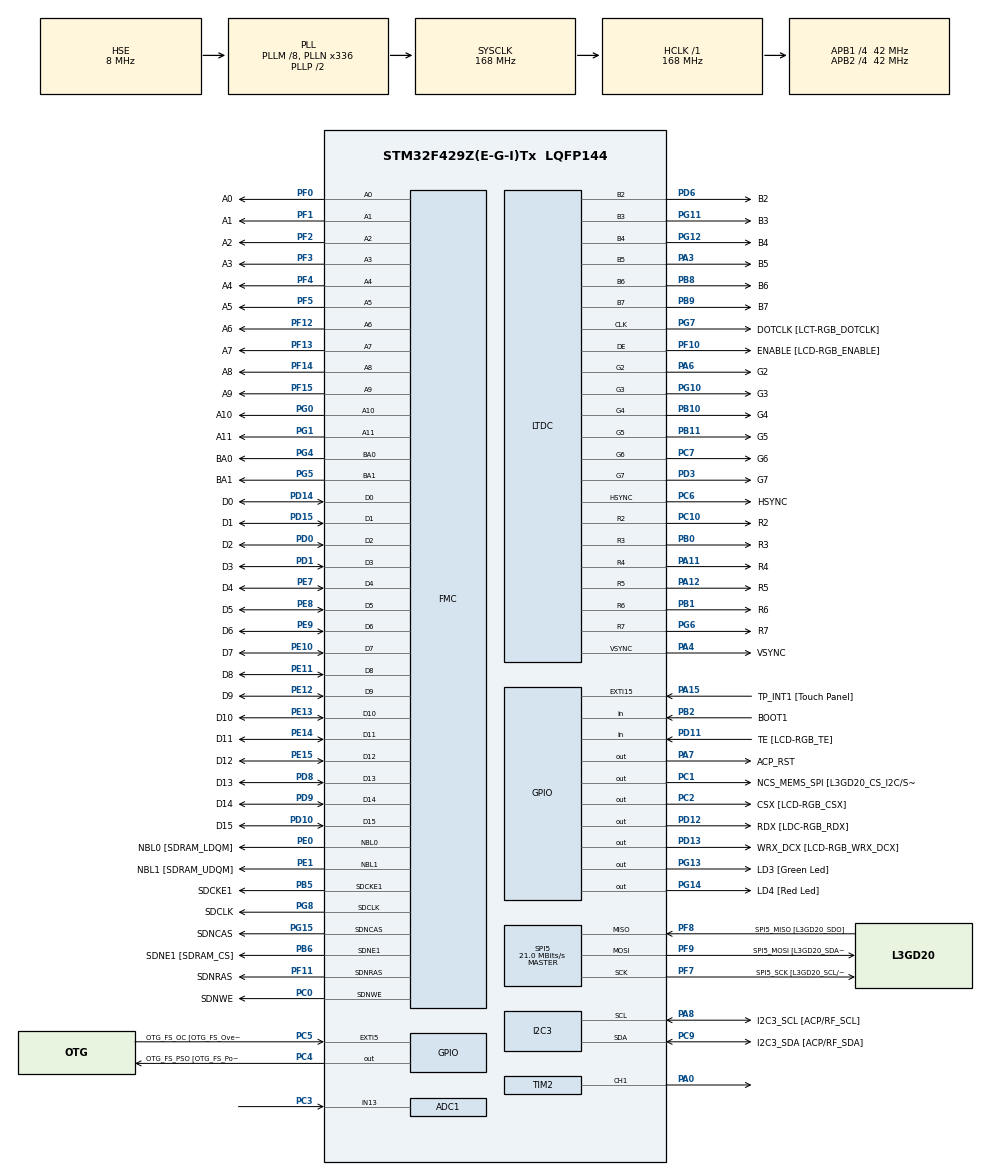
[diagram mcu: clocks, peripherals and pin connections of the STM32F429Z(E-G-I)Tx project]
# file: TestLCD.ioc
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ADC1.Channel-4\#ChannelRegularConversion=ADC_CHANNEL_13
ADC1.ClockPrescaler=ADC_CLOCK_SYNC_PCLK_DIV8
ADC1.NbrOfConversionFlag=1
ADC1.Rank-4\#ChannelRegularConversion=1
ADC1.SamplingTime-4\#ChannelRegularConversion=ADC_SAMPLETIME_15CYCLES
ADC1.ScanConvMode=ENABLE
ADC1.master=1
DMA2D.ColorMode=DMA2D_OUTPUT_RGB565
LTDC.ActiveH=240
LTDC.ActiveW=320
Mcu.Family=STM32F4
Mcu.Name=STM32F429Z(E-G-I)Tx
Mcu.Package=LQFP144
NVIC.PriorityGroup=NVIC_PRIORITYGROUP_0
NVIC.TIM1_UP_TIM10_IRQn=true\:0\:0\:false\:false\:true\:true
PA0/WKUP.Signal=S_TIM2_CH1_ETR
PA11.GPIO_Label=R4
PA11.GPIO_Mode=GPIO_MODE_AF_PP
PA11.GPIO_PuPd=GPIO_NOPULL
PA11.GPIO_Speed=GPIO_SPEED_FREQ_LOW
PA11.Mode=RGB666
PA11.Signal=LTDC_R4
PA12.GPIO_Label=R5
PA12.GPIO_Mode=GPIO_MODE_AF_PP
PA12.GPIO_PuPd=GPIO_NOPULL
PA12.GPIO_Speed=GPIO_SPEED_FREQ_LOW
PA12.Mode=RGB666
PA12.Signal=LTDC_R5
PA13.GPIO_Label=SWDIO
PA13.Mode=Serial_Wire
PA13.Signal=SYS_JTMS-SWDIO
PA14.GPIO_Label=SWCLK
PA14.Mode=Serial_Wire
PA14.Signal=SYS_JTCK-SWCLK
PA15.GPIO_Label=TP_INT1 [Touch Panel]
PA15.GPIO_ModeDefaultEXTI=GPIO_MODE_EVT_RISING
PA15.GPIO_PuPd=GPIO_NOPULL
PA15.Signal=GPXTI15
PA3.GPIO_Label=B5
PA3.GPIO_Mode=GPIO_MODE_AF_PP
PA3.GPIO_PuPd=GPIO_NOPULL
PA3.GPIO_Speed=GPIO_SPEED_FREQ_LOW
PA3.Mode=RGB666
PA3.Signal=LTDC_B5
PA4.GPIO_Label=VSYNC
PA4.GPIO_Mode=GPIO_MODE_AF_PP
PA4.GPIO_PuPd=GPIO_NOPULL
PA4.GPIO_Speed=GPIO_SPEED_FREQ_LOW
PA4.Mode=RGB666
PA4.Signal=LTDC_VSYNC
PA6.GPIO_Label=G2
PA6.GPIO_Mode=GPIO_MODE_AF_PP
PA6.GPIO_PuPd=GPIO_NOPULL
PA6.GPIO_Speed=GPIO_SPEED_FREQ_LOW
PA6.Mode=RGB666
PA6.Signal=LTDC_G2
PA7.GPIO_Label=ACP_RST
PA7.GPIO_Mode=GPIO_MODE_OUTPUT_PP
PA7.GPIO_PuPd=GPIO_NOPULL
PA7.GPIO_Speed=GPIO_SPEED_FREQ_LOW
PA7.Signal=GPIO_Output
PA8.GPIO_Label=I2C3_SCL [ACP/RF_SCL]
PA8.GPIO_Mode=GPIO_MODE_AF_OD
PA8.GPIO_PuPd=GPIO_NOPULL
PA8.GPIO_Speed=GPIO_SPEED_FREQ_LOW
PA8.Mode=I2C
PA8.Signal=I2C3_SCL
PB0.GPIO_Label=R3
PB0.GPIO_Mode=GPIO_MODE_AF_PP
PB0.GPIO_PuPd=GPIO_NOPULL
PB0.GPIO_Speed=GPIO_SPEED_FREQ_LOW
PB0.Mode=RGB666
PB0.Signal=LTDC_R3
PB1.GPIO_Label=R6
PB1.GPIO_Mode=GPIO_MODE_AF_PP
PB1.GPIO_PuPd=GPIO_NOPULL
PB1.GPIO_Speed=GPIO_SPEED_FREQ_LOW
PB1.Mode=RGB666
PB1.Signal=LTDC_R6
PB10.GPIO_Label=G4
PB10.GPIO_Mode=GPIO_MODE_AF_PP
PB10.GPIO_PuPd=GPIO_NOPULL
PB10.GPIO_Speed=GPIO_SPEED_FREQ_LOW
PB10.Mode=RGB666
PB10.Signal=LTDC_G4
PB11.GPIO_Label=G5
PB11.GPIO_Mode=GPIO_MODE_AF_PP
PB11.GPIO_PuPd=GPIO_NOPULL
PB11.GPIO_Speed=GPIO_SPEED_FREQ_LOW
PB11.Mode=RGB666
PB11.Signal=LTDC_G5
PB12.GPIO_Label=OTG_FS_ID
PB12.GPIO_Mode=GPIO_MODE_AF_PP
PB12.GPIO_PuPd=GPIO_NOPULL
PB12.GPIO_Speed=GPIO_SPEED_FREQ_LOW
PB12.Signal=USB_OTG_HS_ID
PB13.GPIO_Label=VBUS_FS
PB13.GPIO_Mode=GPIO_MODE_INPUT
PB13.GPIO_PuPd=GPIO_NOPULL
PB13.Signal=USB_OTG_HS_VBUS
PB14.GPIO_Label=OTG_FS_DM
PB14.GPIO_Mode=GPIO_MODE_AF_PP
PB14.GPIO_PuPd=GPIO_NOPULL
PB14.GPIO_Speed=GPIO_SPEED_FREQ_LOW
PB14.Signal=USB_OTG_HS_DM
PB15.GPIO_Label=OTG_FS_DP
PB15.GPIO_Mode=GPIO_MODE_AF_PP
PB15.GPIO_PuPd=GPIO_NOPULL
PB15.GPIO_Speed=GPIO_SPEED_FREQ_LOW
PB15.Signal=USB_OTG_HS_DP
PB2/BOOT1.GPIO_Label=BOOT1
PB2/BOOT1.GPIO_Mode=GPIO_MODE_INPUT
PB2/BOOT1.GPIO_PuPd=GPIO_NOPULL
PB2/BOOT1.Signal=GPIO_Input
PB5.GPIO_Label=SDCKE1
PB5.GPIO_Mode=GPIO_MODE_AF_PP
PB5.GPIO_PuPd=GPIO_NOPULL
PB5.GPIO_Speed=GPIO_SPEED_FREQ_VERY_HIGH
PB5.Mode=SdramChipSelect2_1
PB5.Signal=FMC_SDCKE1
PB6.GPIO_Label=SDNE1 [SDRAM_CS]
PB6.GPIO_Mode=GPIO_MODE_AF_PP
PB6.GPIO_PuPd=GPIO_NOPULL
PB6.GPIO_Speed=GPIO_SPEED_FREQ_VERY_HIGH
PB6.Mode=SdramChipSelect2_1
PB6.Signal=FMC_SDNE1
PB8.GPIO_Label=B6
PB8.GPIO_Mode=GPIO_MODE_AF_PP
PB8.GPIO_PuPd=GPIO_NOPULL
PB8.GPIO_Speed=GPIO_SPEED_FREQ_LOW
PB8.Mode=RGB666
PB8.Signal=LTDC_B6
PB9.GPIO_Label=B7
PB9.GPIO_Mode=GPIO_MODE_AF_PP
PB9.GPIO_PuPd=GPIO_NOPULL
PB9.GPIO_Speed=GPIO_SPEED_FREQ_LOW
PB9.Mode=RGB666
PB9.Signal=LTDC_B7
PC0.GPIO_Label=SDNWE
PC0.GPIO_Mode=GPIO_MODE_AF_PP
PC0.GPIO_PuPd=GPIO_NOPULL
PC0.GPIO_Speed=GPIO_SPEED_FREQ_VERY_HIGH
PC0.Signal=FMC_SDNWE
PC1.GPIO_Label=NCS_MEMS_SPI [L3GD20_CS_I2C/SPI]
PC1.GPIO_Mode=GPIO_MODE_OUTPUT_PP
PC1.GPIO_PuPd=GPIO_NOPULL
PC1.GPIO_Speed=GPIO_SPEED_FREQ_LOW
PC1.Signal=GPIO_Output
PC10.GPIO_Label=R2
PC10.GPIO_Mode=GPIO_MODE_AF_PP
PC10.GPIO_PuPd=GPIO_NOPULL
PC10.GPIO_Speed=GPIO_SPEED_FREQ_LOW
PC10.Mode=RGB666
PC10.Signal=LTDC_R2
PC14/OSC32_IN.GPIO_Label=PC14-OSC32_IN
PC14/OSC32_IN.Signal=RCC_OSC32_IN
PC15/OSC32_OUT.GPIO_Label=PC15-OSC32_OUT
PC15/OSC32_OUT.Signal=RCC_OSC32_OUT
PC2.GPIO_Label=CSX [LCD-RGB_CSX]
PC2.GPIO_Mode=GPIO_MODE_OUTPUT_PP
PC2.GPIO_PuPd=GPIO_NOPULL
PC2.GPIO_Speed=GPIO_SPEED_FREQ_LOW
PC2.Signal=GPIO_Output
PC3.Signal=ADCx_IN13
PC4.GPIO_Label=OTG_FS_PSO [OTG_FS_PowerSwitchOn]
PC4.GPIO_Mode=GPIO_MODE_OUTPUT_PP
PC4.GPIO_PuPd=GPIO_NOPULL
PC4.GPIO_Speed=GPIO_SPEED_FREQ_LOW
PC4.Signal=GPIO_Output
PC5.GPIO_Label=OTG_FS_OC [OTG_FS_OverCurrent]
PC5.GPIO_ModeDefaultEXTI=GPIO_MODE_EVT_RISING
PC5.Signal=GPXTI5
PC6.GPIO_Label=HSYNC
PC6.GPIO_Mode=GPIO_MODE_AF_PP
PC6.GPIO_PuPd=GPIO_NOPULL
PC6.GPIO_Speed=GPIO_SPEED_FREQ_LOW
PC6.Mode=RGB666
PC6.Signal=LTDC_HSYNC
PC7.GPIO_Label=G6
PC7.GPIO_Mode=GPIO_MODE_AF_PP
PC7.GPIO_PuPd=GPIO_NOPULL
PC7.GPIO_Speed=GPIO_SPEED_FREQ_LOW
PC7.Mode=RGB666
PC7.Signal=LTDC_G6
PC9.GPIO_Label=I2C3_SDA [ACP/RF_SDA]
PC9.GPIO_Mode=GPIO_MODE_AF_OD
PC9.GPIO_PuPd=GPIO_NOPULL
PC9.GPIO_Speed=GPIO_SPEED_FREQ_LOW
PC9.Mode=I2C
PC9.Signal=I2C3_SDA
PD0.GPIO_Label=D2
PD0.GPIO_Mode=GPIO_MODE_AF_PP
PD0.GPIO_PuPd=GPIO_NOPULL
PD0.GPIO_Speed=GPIO_SPEED_FREQ_VERY_HIGH
PD0.Signal=FMC_D2_DA2
PD1.GPIO_Label=D3
PD1.GPIO_Mode=GPIO_MODE_AF_PP
PD1.GPIO_PuPd=GPIO_NOPULL
PD1.GPIO_Speed=GPIO_SPEED_FREQ_VERY_HIGH
PD1.Signal=FMC_D3_DA3
PD10.GPIO_Label=D15
PD10.GPIO_Mode=GPIO_MODE_AF_PP
PD10.GPIO_PuPd=GPIO_NOPULL
PD10.GPIO_Speed=GPIO_SPEED_FREQ_VERY_HIGH
PD10.Signal=FMC_D15_DA15
PD11.GPIO_Label=TE [LCD-RGB_TE]
PD11.GPIO_Mode=GPIO_MODE_INPUT
PD11.GPIO_PuPd=GPIO_NOPULL
PD11.Signal=GPIO_Input
PD12.GPIO_Label=RDX [LDC-RGB_RDX]
PD12.GPIO_Mode=GPIO_MODE_OUTPUT_PP
PD12.GPIO_PuPd=GPIO_NOPULL
PD12.GPIO_Speed=GPIO_SPEED_FREQ_LOW
PD12.Signal=GPIO_Output
PD13.GPIO_Label=WRX_DCX [LCD-RGB_WRX_DCX]
PD13.GPIO_Mode=GPIO_MODE_OUTPUT_PP
PD13.GPIO_PuPd=GPIO_NOPULL
PD13.GPIO_Speed=GPIO_SPEED_FREQ_LOW
PD13.Signal=GPIO_Output
PD14.GPIO_Label=D0
PD14.GPIO_Mode=GPIO_MODE_AF_PP
PD14.GPIO_PuPd=GPIO_NOPULL
PD14.GPIO_Speed=GPIO_SPEED_FREQ_VERY_HIGH
PD14.Signal=FMC_D0_DA0
PD15.GPIO_Label=D1
PD15.GPIO_Mode=GPIO_MODE_AF_PP
PD15.GPIO_PuPd=GPIO_NOPULL
PD15.GPIO_Speed=GPIO_SPEED_FREQ_VERY_HIGH
PD15.Signal=FMC_D1_DA1
PD3.GPIO_Label=G7
PD3.GPIO_Mode=GPIO_MODE_AF_PP
PD3.GPIO_PuPd=GPIO_NOPULL
PD3.GPIO_Speed=GPIO_SPEED_FREQ_LOW
PD3.Mode=RGB666
PD3.Signal=LTDC_G7
PD6.GPIO_Label=B2
PD6.GPIO_Mode=GPIO_MODE_AF_PP
PD6.GPIO_PuPd=GPIO_NOPULL
PD6.GPIO_Speed=GPIO_SPEED_FREQ_LOW
PD6.Mode=RGB666
PD6.Signal=LTDC_B2
PD8.GPIO_Label=D13
PD8.GPIO_Mode=GPIO_MODE_AF_PP
PD8.GPIO_PuPd=GPIO_NOPULL
PD8.GPIO_Speed=GPIO_SPEED_FREQ_VERY_HIGH
PD8.Signal=FMC_D13_DA13
PD9.GPIO_Label=D14
PD9.GPIO_Mode=GPIO_MODE_AF_PP
PD9.GPIO_PuPd=GPIO_NOPULL
PD9.GPIO_Speed=GPIO_SPEED_FREQ_VERY_HIGH
PD9.Signal=FMC_D14_DA14
PE0.GPIO_Label=NBL0 [SDRAM_LDQM]
PE0.GPIO_Mode=GPIO_MODE_AF_PP
PE0.GPIO_PuPd=GPIO_NOPULL
PE0.GPIO_Speed=GPIO_SPEED_FREQ_VERY_HIGH
PE0.Signal=FMC_NBL0
PE1.GPIO_Label=NBL1 [SDRAM_UDQM]
PE1.GPIO_Mode=GPIO_MODE_AF_PP
PE1.GPIO_PuPd=GPIO_NOPULL
PE1.GPIO_Speed=GPIO_SPEED_FREQ_VERY_HIGH
PE1.Signal=FMC_NBL1
PE10.GPIO_Label=D7
PE10.GPIO_Mode=GPIO_MODE_AF_PP
PE10.GPIO_PuPd=GPIO_NOPULL
PE10.GPIO_Speed=GPIO_SPEED_FREQ_VERY_HIGH
PE10.Signal=FMC_D7_DA7
PE11.GPIO_Label=D8
PE11.GPIO_Mode=GPIO_MODE_AF_PP
PE11.GPIO_PuPd=GPIO_NOPULL
PE11.GPIO_Speed=GPIO_SPEED_FREQ_VERY_HIGH
PE11.Signal=FMC_D8_DA8
PE12.GPIO_Label=D9
PE12.GPIO_Mode=GPIO_MODE_AF_PP
PE12.GPIO_PuPd=GPIO_NOPULL
PE12.GPIO_Speed=GPIO_SPEED_FREQ_VERY_HIGH
PE12.Signal=FMC_D9_DA9
PE13.GPIO_Label=D10
PE13.GPIO_Mode=GPIO_MODE_AF_PP
PE13.GPIO_PuPd=GPIO_NOPULL
PE13.GPIO_Speed=GPIO_SPEED_FREQ_VERY_HIGH
PE13.Signal=FMC_D10_DA10
PE14.GPIO_Label=D11
PE14.GPIO_Mode=GPIO_MODE_AF_PP
PE14.GPIO_PuPd=GPIO_NOPULL
PE14.GPIO_Speed=GPIO_SPEED_FREQ_VERY_HIGH
PE14.Signal=FMC_D11_DA11
PE15.GPIO_Label=D12
PE15.GPIO_Mode=GPIO_MODE_AF_PP
PE15.GPIO_PuPd=GPIO_NOPULL
PE15.GPIO_Speed=GPIO_SPEED_FREQ_VERY_HIGH
PE15.Signal=FMC_D12_DA12
PE7.GPIO_Label=D4
PE7.GPIO_Mode=GPIO_MODE_AF_PP
PE7.GPIO_PuPd=GPIO_NOPULL
PE7.GPIO_Speed=GPIO_SPEED_FREQ_VERY_HIGH
PE7.Signal=FMC_D4_DA4
PE8.GPIO_Label=D5
PE8.GPIO_Mode=GPIO_MODE_AF_PP
PE8.GPIO_PuPd=GPIO_NOPULL
PE8.GPIO_Speed=GPIO_SPEED_FREQ_VERY_HIGH
PE8.Signal=FMC_D5_DA5
PE9.GPIO_Label=D6
PE9.GPIO_Mode=GPIO_MODE_AF_PP
PE9.GPIO_PuPd=GPIO_NOPULL
PE9.GPIO_Speed=GPIO_SPEED_FREQ_VERY_HIGH
PE9.Signal=FMC_D6_DA6
PF0.GPIO_Label=A0
PF0.GPIO_Mode=GPIO_MODE_AF_PP
PF0.GPIO_PuPd=GPIO_NOPULL
PF0.GPIO_Speed=GPIO_SPEED_FREQ_VERY_HIGH
PF0.Signal=FMC_A0
PF1.GPIO_Label=A1
PF1.GPIO_Mode=GPIO_MODE_AF_PP
PF1.GPIO_PuPd=GPIO_NOPULL
PF1.GPIO_Speed=GPIO_SPEED_FREQ_VERY_HIGH
PF1.Signal=FMC_A1
PF10.GPIO_Label=ENABLE [LCD-RGB_ENABLE]
PF10.GPIO_Mode=GPIO_MODE_AF_PP
PF10.GPIO_PuPd=GPIO_NOPULL
PF10.GPIO_Speed=GPIO_SPEED_FREQ_LOW
PF10.Mode=RGB666
PF10.Signal=LTDC_DE
PF11.GPIO_Label=SDNRAS
PF11.GPIO_Mode=GPIO_MODE_AF_PP
PF11.GPIO_PuPd=GPIO_NOPULL
PF11.GPIO_Speed=GPIO_SPEED_FREQ_VERY_HIGH
PF11.Signal=FMC_SDNRAS
PF12.GPIO_Label=A6
PF12.GPIO_Mode=GPIO_MODE_AF_PP
PF12.GPIO_PuPd=GPIO_NOPULL
PF12.GPIO_Speed=GPIO_SPEED_FREQ_VERY_HIGH
PF12.Signal=FMC_A6
PF13.GPIO_Label=A7
PF13.GPIO_Mode=GPIO_MODE_AF_PP
PF13.GPIO_PuPd=GPIO_NOPULL
PF13.GPIO_Speed=GPIO_SPEED_FREQ_VERY_HIGH
PF13.Signal=FMC_A7
PF14.GPIO_Label=A8
PF14.GPIO_Mode=GPIO_MODE_AF_PP
PF14.GPIO_PuPd=GPIO_NOPULL
PF14.GPIO_Speed=GPIO_SPEED_FREQ_VERY_HIGH
PF14.Signal=FMC_A8
PF15.GPIO_Label=A9
PF15.GPIO_Mode=GPIO_MODE_AF_PP
PF15.GPIO_PuPd=GPIO_NOPULL
PF15.GPIO_Speed=GPIO_SPEED_FREQ_VERY_HIGH
PF15.Signal=FMC_A9
PF2.GPIO_Label=A2
PF2.GPIO_Mode=GPIO_MODE_AF_PP
PF2.GPIO_PuPd=GPIO_NOPULL
PF2.GPIO_Speed=GPIO_SPEED_FREQ_VERY_HIGH
PF2.Signal=FMC_A2
PF3.GPIO_Label=A3
PF3.GPIO_Mode=GPIO_MODE_AF_PP
PF3.GPIO_PuPd=GPIO_NOPULL
PF3.GPIO_Speed=GPIO_SPEED_FREQ_VERY_HIGH
PF3.Signal=FMC_A3
PF4.GPIO_Label=A4
PF4.GPIO_Mode=GPIO_MODE_AF_PP
PF4.GPIO_PuPd=GPIO_NOPULL
PF4.GPIO_Speed=GPIO_SPEED_FREQ_VERY_HIGH
PF4.Signal=FMC_A4
PF5.GPIO_Label=A5
PF5.GPIO_Mode=GPIO_MODE_AF_PP
PF5.GPIO_PuPd=GPIO_NOPULL
PF5.GPIO_Speed=GPIO_SPEED_FREQ_VERY_HIGH
PF5.Signal=FMC_A5
PF7.GPIO_Label=SPI5_SCK [L3GD20_SCL/SPC]
PF7.GPIO_Mode=GPIO_MODE_AF_PP
PF7.GPIO_PuPd=GPIO_NOPULL
PF7.GPIO_Speed=GPIO_SPEED_FREQ_LOW
PF7.Mode=Full_Duplex_Master
PF7.Signal=SPI5_SCK
PF8.GPIO_Label=SPI5_MISO [L3GD20_SDO]
PF8.GPIO_Mode=GPIO_MODE_AF_PP
PF8.GPIO_PuPd=GPIO_NOPULL
PF8.GPIO_Speed=GPIO_SPEED_FREQ_LOW
PF8.Mode=Full_Duplex_Master
PF8.Signal=SPI5_MISO
PF9.GPIO_Label=SPI5_MOSI [L3GD20_SDA/SDI/SDO]
PF9.GPIO_Mode=GPIO_MODE_AF_PP
PF9.GPIO_PuPd=GPIO_NOPULL
PF9.GPIO_Speed=GPIO_SPEED_FREQ_LOW
PF9.Mode=Full_Duplex_Master
PF9.Signal=SPI5_MOSI
PG0.GPIO_Label=A10
PG0.GPIO_Mode=GPIO_MODE_AF_PP
PG0.GPIO_PuPd=GPIO_NOPULL
PG0.GPIO_Speed=GPIO_SPEED_FREQ_VERY_HIGH
PG0.Signal=FMC_A10
PG1.GPIO_Label=A11
PG1.GPIO_Mode=GPIO_MODE_AF_PP
PG1.GPIO_PuPd=GPIO_NOPULL
PG1.GPIO_Speed=GPIO_SPEED_FREQ_VERY_HIGH
PG1.Signal=FMC_A11
PG10.GPIO_Label=G3
PG10.GPIO_Mode=GPIO_MODE_AF_PP
PG10.GPIO_PuPd=GPIO_NOPULL
PG10.GPIO_Speed=GPIO_SPEED_FREQ_LOW
PG10.Mode=RGB666
PG10.Signal=LTDC_G3
PG11.GPIO_Label=B3
PG11.GPIO_Mode=GPIO_MODE_AF_PP
PG11.GPIO_PuPd=GPIO_NOPULL
PG11.GPIO_Speed=GPIO_SPEED_FREQ_LOW
PG11.Mode=RGB666
PG11.Signal=LTDC_B3
PG12.GPIO_Label=B4
PG12.GPIO_Mode=GPIO_MODE_AF_PP
PG12.GPIO_PuPd=GPIO_NOPULL
PG12.GPIO_Speed=GPIO_SPEED_FREQ_LOW
PG12.Mode=RGB666
PG12.Signal=LTDC_B4
PG13.GPIO_Label=LD3 [Green Led]
PG13.GPIO_Mode=GPIO_MODE_OUTPUT_PP
PG13.GPIO_PuPd=GPIO_NOPULL
PG13.GPIO_Speed=GPIO_SPEED_FREQ_LOW
PG13.Signal=GPIO_Output
PG14.GPIO_Label=LD4 [Red Led]
PG14.GPIO_Mode=GPIO_MODE_OUTPUT_PP
PG14.GPIO_PuPd=GPIO_NOPULL
PG14.GPIO_Speed=GPIO_SPEED_FREQ_LOW
PG14.Signal=GPIO_Output
PG15.GPIO_Label=SDNCAS
PG15.GPIO_Mode=GPIO_MODE_AF_PP
PG15.GPIO_PuPd=GPIO_NOPULL
PG15.GPIO_Speed=GPIO_SPEED_FREQ_VERY_HIGH
PG15.Signal=FMC_SDNCAS
PG4.GPIO_Label=BA0
PG4.GPIO_Mode=GPIO_MODE_AF_PP
PG4.GPIO_PuPd=GPIO_NOPULL
PG4.GPIO_Speed=GPIO_SPEED_FREQ_VERY_HIGH
PG4.Signal=FMC_A14_BA0
PG5.GPIO_Label=BA1
PG5.GPIO_Mode=GPIO_MODE_AF_PP
PG5.GPIO_PuPd=GPIO_NOPULL
PG5.GPIO_Speed=GPIO_SPEED_FREQ_VERY_HIGH
PG5.Signal=FMC_A15_BA1
PG6.GPIO_Label=R7
PG6.GPIO_Mode=GPIO_MODE_AF_PP
PG6.GPIO_PuPd=GPIO_NOPULL
PG6.GPIO_Speed=GPIO_SPEED_FREQ_LOW
PG6.Mode=RGB666
PG6.Signal=LTDC_R7
PG7.GPIO_Label=DOTCLK [LCT-RGB_DOTCLK]
PG7.GPIO_Mode=GPIO_MODE_AF_PP
PG7.GPIO_PuPd=GPIO_NOPULL
PG7.GPIO_Speed=GPIO_SPEED_FREQ_LOW
PG7.Mode=RGB666
PG7.Signal=LTDC_CLK
PG8.GPIO_Label=SDCLK
PG8.GPIO_Mode=GPIO_MODE_AF_PP
PG8.GPIO_PuPd=GPIO_NOPULL
PG8.GPIO_Speed=GPIO_SPEED_FREQ_VERY_HIGH
PG8.Signal=FMC_SDCLK
PH0/OSC_IN.GPIO_Label=PH0-OSC_IN
PH0/OSC_IN.Mode=HSE-External-Oscillator
PH0/OSC_IN.Signal=RCC_OSC_IN
PH1/OSC_OUT.GPIO_Label=PH1-OSC_OUT
PH1/OSC_OUT.Mode=HSE-External-Oscillator
PH1/OSC_OUT.Signal=RCC_OSC_OUT
ProjectManager.HeapSize=0x1000
ProjectManager.StackSize=0x1000
ProjectManager.TargetToolchain=SW4STM32
RCC.48MHZClocksFreq_Value=48000000
RCC.AHBFreq_Value=168000000
RCC.APB1CLKDivider=RCC_HCLK_DIV4
RCC.APB1Freq_Value=42000000
RCC.APB1TimFreq_Value=84000000
RCC.APB2CLKDivider=RCC_HCLK_DIV4
RCC.APB2Freq_Value=42000000
RCC.APB2TimFreq_Value=84000000
RCC.CortexFreq_Value=168000000
RCC.HCLKFreq_Value=168000000
RCC.HSE_VALUE=8000000
RCC.HSI_VALUE=16000000
RCC.LSE_VALUE=32768
RCC.PLLM=8
RCC.PLLN=336
RCC.PLLQ=7
RCC.PLLSAIN=216
RCC.PLLSourceVirtual=RCC_PLLSOURCE_HSE
RCC.SYSCLKFreq_VALUE=168000000
RCC.SYSCLKSource=RCC_SYSCLKSOURCE_PLLCLK
RCC.VCOOutputFreq_Value=336000000
SH.ADCx_IN13.0=ADC1_IN13,IN13
SH.FMC_A0.0=FMC_A0,12b-sda1
SH.FMC_A1.0=FMC_A1,12b-sda1
SH.FMC_A10.0=FMC_A10,12b-sda1
SH.FMC_A11.0=FMC_A11,12b-sda1
SH.FMC_A14_BA0.0=FMC_BA0,FourSdramBanks1
SH.FMC_A15_BA1.0=FMC_BA1,FourSdramBanks1
SH.FMC_A2.0=FMC_A2,12b-sda1
SH.FMC_A3.0=FMC_A3,12b-sda1
SH.FMC_A4.0=FMC_A4,12b-sda1
SH.FMC_A5.0=FMC_A5,12b-sda1
SH.FMC_A6.0=FMC_A6,12b-sda1
SH.FMC_A7.0=FMC_A7,12b-sda1
SH.FMC_A8.0=FMC_A8,12b-sda1
SH.FMC_A9.0=FMC_A9,12b-sda1
SH.FMC_D0_DA0.0=FMC_D0,sd-16b-d1
SH.FMC_D10_DA10.0=FMC_D10,sd-16b-d1
SH.FMC_D11_DA11.0=FMC_D11,sd-16b-d1
SH.FMC_D12_DA12.0=FMC_D12,sd-16b-d1
SH.FMC_D13_DA13.0=FMC_D13,sd-16b-d1
SH.FMC_D14_DA14.0=FMC_D14,sd-16b-d1
SH.FMC_D15_DA15.0=FMC_D15,sd-16b-d1
SH.FMC_D1_DA1.0=FMC_D1,sd-16b-d1
SH.FMC_D2_DA2.0=FMC_D2,sd-16b-d1
SH.FMC_D3_DA3.0=FMC_D3,sd-16b-d1
SH.FMC_D4_DA4.0=FMC_D4,sd-16b-d1
SH.FMC_D5_DA5.0=FMC_D5,sd-16b-d1
SH.FMC_D6_DA6.0=FMC_D6,sd-16b-d1
SH.FMC_D7_DA7.0=FMC_D7,sd-16b-d1
SH.FMC_D8_DA8.0=FMC_D8,sd-16b-d1
SH.FMC_D9_DA9.0=FMC_D9,sd-16b-d1
SH.FMC_NBL0.0=FMC_NBL0,Sd2ByteEnable1
SH.FMC_NBL1.0=FMC_NBL1,Sd2ByteEnable1
SH.FMC_SDCLK.0=FMC_SDCLK,12b-sda1
SH.FMC_SDNCAS.0=FMC_SDNCAS,12b-sda1
SH.FMC_SDNRAS.0=FMC_SDNRAS,12b-sda1
SH.FMC_SDNWE.0=FMC_SDNWE,12b-sda1
SH.S_TIM2_CH1_ETR.0=TIM2_CH1,PWM Generation1 CH1
SPI5.CalculateBaudRate=21.0 MBits/s
SPI5.Direction=SPI_DIRECTION_2LINES
SPI5.Mode=SPI_MODE_MASTER
SPI5.VirtualType=VM_MASTER
TIM1.Period=100
TIM1.Prescaler=42000
TIM2.Channel-PWM\ Generation1\ CH1=TIM_CHANNEL_1
TIM2.Period=99
TIM2.Prescaler=420
VP_DMA2D_VS_DMA2D.Mode=DMA2D_Activate
VP_TIM1_VS_ClockSourceINT.Mode=Internal
VP_TIM2_VS_ClockSourceINT.Mode=Internal
board=STM32F429I-DISCO

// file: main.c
/**
  ******************************************************************************
  * File Name          : main.c
  * Description        : Main program body
  ******************************************************************************
  ** This notice applies to any and all portions of this file
  * that are not between comment pairs USER CODE BEGIN and
  * USER CODE END. Other portions of this file, whether
  * inserted by the user or by software development tools
  * are owned by their respective copyright owners.
  *
  * COPYRIGHT(c) 2017 STMicroelectronics
  *
  * Redistribution and use in source and binary forms, with or without modification,
  * are permitted provided that the following conditions are met:
  *   1. Redistributions of source code must retain the above copyright notice,
  *      this list of conditions and the following disclaimer.
  *   2. Redistributions in binary form must reproduce the above copyright notice,
  *      this list of conditions and the following disclaimer in the documentation
  *      and/or other materials provided with the distribution.
  *   3. Neither the name of STMicroelectronics nor the names of its contributors
  *      may be used to endorse or promote products derived from this software
  *      without specific prior written permission.
  *
  * THIS SOFTWARE IS PROVIDED BY THE COPYRIGHT HOLDERS AND CONTRIBUTORS "AS IS"
  * AND ANY EXPRESS OR IMPLIED WARRANTIES, INCLUDING, BUT NOT LIMITED TO, THE
  * IMPLIED WARRANTIES OF MERCHANTABILITY AND FITNESS FOR A PARTICULAR PURPOSE ARE
  * DISCLAIMED. IN NO EVENT SHALL THE COPYRIGHT HOLDER OR CONTRIBUTORS BE LIABLE
  * FOR ANY DIRECT, INDIRECT, INCIDENTAL, SPECIAL, EXEMPLARY, OR CONSEQUENTIAL
  * DAMAGES (INCLUDING, BUT NOT LIMITED TO, PROCUREMENT OF SUBSTITUTE GOODS OR
  * SERVICES; LOSS OF USE, DATA, OR PROFITS; OR BUSINESS INTERRUPTION) HOWEVER
  * CAUSED AND ON ANY THEORY OF LIABILITY, WHETHER IN CONTRACT, STRICT LIABILITY,
  * OR TORT (INCLUDING NEGLIGENCE OR OTHERWISE) ARISING IN ANY WAY OUT OF THE USE
  * OF THIS SOFTWARE, EVEN IF ADVISED OF THE POSSIBILITY OF SUCH DAMAGE.
  *
  ******************************************************************************
  */
#include "main.h"
#include "stm32f4xx_hal.h"
#include "adc.h"
#include "dma2d.h"
#include "i2c.h"
#include "ltdc.h"
#include "spi.h"
#include "tim.h"
#include "gpio.h"
#include "fmc.h"

/* USER CODE BEGIN Includes */
#include "stm32f429i_discovery_lcd.h"
#include "stm32f429i_discovery_sdram.h"
#include "stm32f429i_discovery_ts.h"
#include "string.h"
#include "LCD_GRAPH.h"
#include "SHT15.h"
/* USER CODE END Includes */

/* USER CODE BEGIN PV */
/* Private variables ---------------------------------------------------------*/
uint16_t raw_humi, raw_temp;
uint8_t count = 0;
float humi_val_real = 0.0;
float temp_val_real = 0.0;
float ad=0, X=0, vel;
/* USER CODE END PV */

void SystemClock_Config(void);

/* USER CODE BEGIN PFP */
/* Private function prototypes -----------------------------------------------*/

/* USER CODE END PFP */

int main(void)
{

  /* USER CODE BEGIN 1 */
	enum{Tplus,Tminus,Uplus,Uminus,Vel};
	uint8_t vetor[30]
					,tMax
					,tMin
					,Umax
					,Umin
					,vMax
					,select;
	int color[5];

	TS_StateTypeDef TsState;
  /* USER CODE END 1 */

  /* MCU Configuration----------------------------------------------------------*/

  /* Reset of all peripherals, Initializes the Flash interface and the Systick. */
  HAL_Init();

  /* Configure the system clock */
  SystemClock_Config();

  /* Initialize all configured peripherals */
  MX_GPIO_Init();
  MX_DMA2D_Init();
  MX_FMC_Init();
  MX_I2C3_Init();
  MX_LTDC_Init();
  MX_SPI5_Init();
  MX_ADC1_Init();
  MX_TIM2_Init();
  MX_TIM1_Init();

  /* USER CODE BEGIN 2 */
  BSP_LCD_Init();
  BSP_LCD_LayerDefaultInit(LCD_BACKGROUND_LAYER,LCD_FRAME_BUFFER);
  BSP_LCD_LayerDefaultInit(LCD_FOREGROUND_LAYER,LCD_FRAME_BUFFER);
  BSP_LCD_SelectLayer(LCD_FOREGROUND_LAYER);
  BSP_LCD_DisplayOn();
  BSP_LCD_Clear(LCD_COLOR_WHITE);
  BSP_TS_Init(240, 320);
  ADC_ChannelConfTypeDef sConfig;

  HAL_TIM_Base_Start_IT(&htim1);
  HAL_TIM_PWM_Start(&htim2,TIM_CHANNEL_1);

  sConfig.Channel = ADC_CHANNEL_13;
  HAL_ADC_ConfigChannel(&hadc1, &sConfig);
  tMax = 30;
  tMin = 15;
  Umax = 75;
  Umin = 50;
  vMax = 50;
  select = Tplus;

  color[0] = LCD_COLOR_BLUE;
  color[1] = LCD_COLOR_BLUE;
  color[2] = LCD_COLOR_BLUE;
  color[3] = LCD_COLOR_BLUE;
  color[4] = LCD_COLOR_BLUE;
  SHT15_Init();
  BSP_LCD_SetTextColor(LCD_COLOR_DARKYELLOW);
  BSP_LCD_DrawHLine(10,40,220);

  BSP_LCD_SetTextColor(LCD_COLOR_DARKYELLOW);
  BSP_LCD_DrawHLine(10,250,220);

  BSP_LCD_SetTextColor(LCD_COLOR_RED);
  BSP_LCD_DrawBitmap(160,120,(uint8_t*)Up);
  BSP_LCD_DrawBitmap(160,160,(uint8_t*)Down);
  BSP_LCD_DrawRect(160,159, 25,25);
  BSP_LCD_DrawRect(160,119, 25,25);

  BSP_LCD_SetFont(&Font16);
  BSP_LCD_SetTextColor(LCD_COLOR_BLUE);
  sprintf((char*)vetor,"      Alarmes");
  BSP_LCD_DisplayStringAtLine(16,(uint8_t*)vetor);
  /* USER CODE END 2 */

  /* Infinite loop */
  while (1)
  {

  /* USER CODE BEGIN 3 */
	if(count == 10){
	SHT15_Measure(&raw_temp, TEMP);
	SHT15_Measure(&raw_humi, HUMI);
	SHT15_Calculate(raw_temp, raw_humi, &temp_val_real, &humi_val_real); //Get the temperature measurement
	}
	ad=(X*3)/4095;
 	vel=ad*(100/3);

 	BSP_LCD_SetFont(&Font16);
	BSP_LCD_SetTextColor(LCD_COLOR_RED);
	sprintf((char*)vetor,"T:%2.1f U:%2.1f%% V:%.2f",temp_val_real, humi_val_real, vel);
	BSP_LCD_DisplayStringAtLine(0,(uint8_t*)vetor);
	BSP_LCD_SetFont(&Font16);
	BSP_LCD_SetTextColor(LCD_COLOR_RED);
	sprintf((char*)vetor,"T:%2.1f U:%2.1f%% V:%.2f",temp_val_real, humi_val_real, vel);
	BSP_LCD_DisplayStringAtLine(0,(uint8_t*)vetor);

	BSP_LCD_SetFont(&Font20);
	BSP_LCD_SetTextColor(color[0]);
	sprintf((char*)vetor,"T.MAX=%2.1d",tMax);
	BSP_LCD_DisplayStringAtLine(3,(uint8_t*)vetor);
	BSP_LCD_SetTextColor(color[1]);
	sprintf((char*)vetor,"T.MIN=%2.1d",tMin);
	BSP_LCD_DisplayStringAtLine(5,(uint8_t*)vetor);
	BSP_LCD_SetTextColor(color[2]);
	sprintf((char*)vetor,"U.MAX=%2.1d",Umax);
	BSP_LCD_DisplayStringAtLine(7,(uint8_t*)vetor);
	BSP_LCD_SetTextColor(color[3]);
	sprintf((char*)vetor,"U.MIN=%2.1d",Umin);
	BSP_LCD_DisplayStringAtLine(9,(uint8_t*)vetor);
	BSP_LCD_SetTextColor(color[4]);
	sprintf((char*)vetor,"V.MAX=%dm/s",vMax);
	BSP_LCD_DisplayStringAtLine(11,(uint8_t*)vetor);
	BSP_LCD_SetTextColor(LCD_COLOR_BLUE);

	BSP_LCD_SetFont(&Font24);
//	sprintf((char*)vetor,"x:%d y:%d ad:%2.2f",TsState.X,TsState.Y,ad);
//	BSP_LCD_DisplayStringAtLine(18,(uint8_t*)vetor);

	/*------------------------------------------------*/
	/* --- Change color of alarm*/
	/*------------------------------------------------*/
	if((humi_val_real > Umax) | (humi_val_real < Umin) ){
		BSP_LCD_SetTextColor(LCD_COLOR_BLUE);
		BSP_LCD_DisplayChar(23,280,'U');
		BSP_LCD_SetTextColor(LCD_COLOR_DARKRED);
		BSP_LCD_DrawCircle(50,290,11);
		BSP_LCD_SetTextColor(LCD_COLOR_RED);
		BSP_LCD_FillCircle(50,290,10);
	}
	else{
		BSP_LCD_SetTextColor(LCD_COLOR_BLUE);
		BSP_LCD_DisplayChar(23,280,'U');
		BSP_LCD_SetTextColor(LCD_COLOR_DARKGREEN);
		BSP_LCD_DrawCircle(50,290,11);
		BSP_LCD_SetTextColor(LCD_COLOR_GREEN);
		BSP_LCD_FillCircle(50,290,10);
	}
	if((temp_val_real > tMax) | (temp_val_real < tMin) ){
		BSP_LCD_SetTextColor(LCD_COLOR_BLUE);
		BSP_LCD_DisplayChar(93,280,'T');
		BSP_LCD_SetTextColor(LCD_COLOR_DARKRED);
		BSP_LCD_DrawCircle(120,290,11);
		BSP_LCD_SetTextColor(LCD_COLOR_RED);
		BSP_LCD_FillCircle(120,290,10);
	}
	else{
		BSP_LCD_SetTextColor(LCD_COLOR_BLUE);
		BSP_LCD_DisplayChar(93,280,'T');
		BSP_LCD_SetTextColor(LCD_COLOR_DARKGREEN);
		BSP_LCD_DrawCircle(120,290,11);
		BSP_LCD_SetTextColor(LCD_COLOR_GREEN);
		BSP_LCD_FillCircle(120,290,10);
	}
	if(vel  >  vMax ){
			BSP_LCD_SetTextColor(LCD_COLOR_BLUE);
			BSP_LCD_DisplayChar(153,280,'V');
			BSP_LCD_SetTextColor(LCD_COLOR_DARKRED);
			BSP_LCD_DrawCircle(180,290,11);
			BSP_LCD_SetTextColor(LCD_COLOR_RED);
			BSP_LCD_FillCircle(180,290,10);
		}
		else{
			BSP_LCD_SetTextColor(LCD_COLOR_BLUE);
			BSP_LCD_DisplayChar(153,280,'V');
			BSP_LCD_SetTextColor(LCD_COLOR_DARKGREEN);
			BSP_LCD_DrawCircle(180,290,11);
			BSP_LCD_SetTextColor(LCD_COLOR_GREEN);
			BSP_LCD_FillCircle(180,290,10);
		}

	/*------------------------------------------------*/

	if((TsState.X > 0) & (TsState.X < 140)){
		if ((TsState.Y >50) & (TsState.Y < 80)){
			color[1] = LCD_COLOR_BLUE;
	  		 color[2] = LCD_COLOR_BLUE;
	  		 color[3] = LCD_COLOR_BLUE;
	  		 color[4] = LCD_COLOR_BLUE;
	  		 color[0] = LCD_COLOR_RED;
	  		 select = Tplus;
		}
		else if ((TsState.Y >90) & (TsState.Y < 110)){
			color[0] = LCD_COLOR_BLUE;
	  		color[2] = LCD_COLOR_BLUE;
	  		color[3] = LCD_COLOR_BLUE;
	  		color[4] = LCD_COLOR_BLUE;
		  	color[1] = LCD_COLOR_RED;
	  		select = Tminus;
		}
		else if ((TsState.Y >140) & (TsState.Y < 150)){
			color[0] = LCD_COLOR_BLUE;
			color[1] = LCD_COLOR_BLUE;
			color[3] = LCD_COLOR_BLUE;
			color[4] = LCD_COLOR_BLUE;
			color[2] = LCD_COLOR_RED;
			select = Uplus;
		}
		else if ((TsState.Y >140) & (TsState.Y < 190)){
			color[0] = LCD_COLOR_BLUE;
			color[1] = LCD_COLOR_BLUE;
			color[2] = LCD_COLOR_BLUE;
			color[4] = LCD_COLOR_BLUE;
			color[3] = LCD_COLOR_RED;
			select = Uminus;
		}
		else if((TsState.Y >210) & (TsState.Y < 240)){
			color[0] = LCD_COLOR_BLUE;
			color[1] = LCD_COLOR_BLUE;
			color[2] = LCD_COLOR_BLUE;
			color[3] = LCD_COLOR_BLUE;
			color[4] = LCD_COLOR_RED;
			select = Vel;
		}
	}

	if(TsState.TouchDetected ==1)	{
		if((TsState.X > 140) & (TsState.X < 210)) 	{
			if ((TsState.Y >150) & (TsState.Y <180))	{
				if(select == Tplus)
					tMax--;
				if(select == Tminus)
					tMin--;
				if(select == Uplus)
					Umax--;
				if(select == Uminus)
					Umin--;
				if(select == Vel)
					vMax--;
			}
		}
		if ((TsState.X > 140) & (TsState.X < 210)){
			if ((TsState.Y >115) & (TsState.Y <150)){
				if(select == Tplus)
					tMax++;
				if(select == Tminus)
					tMin++;
				if(select == Uplus)
					Umax++;
				if(select == Uminus)
					Umin++;
				if(select == Vel)
					vMax++;
			}
		}
	}

	 HAL_Delay(100);
	 BSP_TS_GetState(&TsState);
  }
  /* USER CODE END 3 */

}

/** System Clock Configuration
*/
void SystemClock_Config(void)
{

  RCC_OscInitTypeDef RCC_OscInitStruct;
  RCC_ClkInitTypeDef RCC_ClkInitStruct;
  RCC_PeriphCLKInitTypeDef PeriphClkInitStruct;

    /**Configure the main internal regulator output voltage
    */
  __HAL_RCC_PWR_CLK_ENABLE();

  __HAL_PWR_VOLTAGESCALING_CONFIG(PWR_REGULATOR_VOLTAGE_SCALE1);

    /**Initializes the CPU, AHB and APB busses clocks
    */
  RCC_OscInitStruct.OscillatorType = RCC_OSCILLATORTYPE_HSE;
  RCC_OscInitStruct.HSEState = RCC_HSE_ON;
  RCC_OscInitStruct.PLL.PLLState = RCC_PLL_ON;
  RCC_OscInitStruct.PLL.PLLSource = RCC_PLLSOURCE_HSE;

  RCC_OscInitStruct.PLL.PLLM = 8;
  RCC_OscInitStruct.PLL.PLLN = 336;
  RCC_OscInitStruct.PLL.PLLP = RCC_PLLP_DIV2;
  RCC_OscInitStruct.PLL.PLLQ = 7;
  if (HAL_RCC_OscConfig(&RCC_OscInitStruct) != HAL_OK)
  {
    _Error_Handler(__FILE__, __LINE__);
  }

    /**Initializes the CPU, AHB and APB busses clocks
    */
  RCC_ClkInitStruct.ClockType = RCC_CLOCKTYPE_HCLK|RCC_CLOCKTYPE_SYSCLK
                              |RCC_CLOCKTYPE_PCLK1|RCC_CLOCKTYPE_PCLK2;
  RCC_ClkInitStruct.SYSCLKSource = RCC_SYSCLKSOURCE_PLLCLK;
  RCC_ClkInitStruct.AHBCLKDivider = RCC_SYSCLK_DIV1;
  RCC_ClkInitStruct.APB1CLKDivider = RCC_HCLK_DIV4;
  RCC_ClkInitStruct.APB2CLKDivider = RCC_HCLK_DIV4;

  if (HAL_RCC_ClockConfig(&RCC_ClkInitStruct, FLASH_LATENCY_5) != HAL_OK)
  {
    _Error_Handler(__FILE__, __LINE__);
  }

  PeriphClkInitStruct.PeriphClockSelection = RCC_PERIPHCLK_LTDC;
  PeriphClkInitStruct.PLLSAI.PLLSAIN = 216;
  PeriphClkInitStruct.PLLSAI.PLLSAIR = 2;
  PeriphClkInitStruct.PLLSAIDivR = RCC_PLLSAIDIVR_2;
  if (HAL_RCCEx_PeriphCLKConfig(&PeriphClkInitStruct) != HAL_OK)
  {
    _Error_Handler(__FILE__, __LINE__);
  }

    /**Configure the Systick interrupt time
    */
  HAL_SYSTICK_Config(HAL_RCC_GetHCLKFreq()/1000);

    /**Configure the Systick
    */
  HAL_SYSTICK_CLKSourceConfig(SYSTICK_CLKSOURCE_HCLK);

  /* SysTick_IRQn interrupt configuration */
  HAL_NVIC_SetPriority(SysTick_IRQn, 0, 0);
}

/* USER CODE BEGIN 4 */
void HAL_TIM_PeriodElapsedCallback(TIM_HandleTypeDef *htim)
{
	if (count > 10)
		count = 0;
	count ++;
 	TIM2->CCR1 = ad*(100/3) - 2;
	 HAL_ADC_Start(&hadc1);
	HAL_ADC_PollForConversion(&hadc1,ADC_CHANNEL_13);
	X = HAL_ADC_GetValue(&hadc1);

}
/* USER CODE END 4 */

void _Error_Handler(char * file, int line)
{
  while(1)
  {
  }
}

/************************ (C) COPYRIGHT STMicroelectronics *****END OF FILE****/
